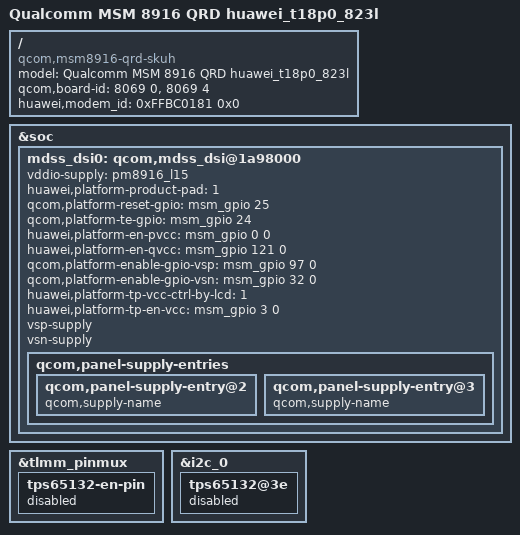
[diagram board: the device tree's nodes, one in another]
/* Copyright (c) 2014, The Linux Foundation. All rights reserved.
 *
 * This program is free software; you can redistribute it and/or modify
 * it under the terms of the GNU General Public License version 2 and
 * only version 2 as published by the Free Software Foundation.
 *
 * This program is distributed in the hope that it will be useful,
 * but WITHOUT ANY WARRANTY; without even the implied warranty of
 * MERCHANTABILITY or FITNESS FOR A PARTICULAR PURPOSE.  See the
 * GNU General Public License for more details.
 */
/dts-v1/;
#include "msm8916-qrd-skuh.dtsi"
#include "msm8916-memory.dtsi"
#include "huawei_msm8916_t18_823l_va/huawei.dtsi"
/ {
	model = "Qualcomm MSM 8916 QRD huawei_t18p0_823l";
	compatible = "qcom,msm8916-qrd-skuh", "qcom,msm8916-qrd", "qcom,msm8916", "qcom,qrd";
	qcom,board-id = <8069 0> , <8069 4>;
	huawei,modem_id = <0xFFBC0181 0x0>;
};

&soc {
	mdss_dsi0: qcom,mdss_dsi@1a98000 {
		vddio-supply = <&pm8916_l15>;
		huawei,platform-product-pad = <1>;
		qcom,platform-reset-gpio = <&msm_gpio 25 0>;
		qcom,platform-te-gpio = <&msm_gpio 24 0>;	
		huawei,platform-en-pvcc = <&msm_gpio 0 0>; 
		huawei,platform-en-qvcc = <&msm_gpio 121 0>; 
		qcom,platform-enable-gpio-vsp = <&msm_gpio 97 0>;
		qcom,platform-enable-gpio-vsn = <&msm_gpio 32 0>; 
		huawei,platform-tp-vcc-ctrl-by-lcd = <1>;
		huawei,platform-tp-en-vcc = <&msm_gpio 3 0>; 		
	};
};

&tlmm_pinmux {
	tps65132-en-pin {
		status = "disabled";
	};
};

&i2c_0 {
	tps65132@3e {
		status = "disabled";
	};
};

&mdss_dsi0 {
	vsp-supply;
	vsn-supply;
	qcom,panel-supply-entries {
		qcom,panel-supply-entry@2 {
			qcom,supply-name;	
		};
		qcom,panel-supply-entry@3 {
			qcom,supply-name;			
		};
	};
};
